# STM32WB55x register map
File version: 1.0
CPU: CM4 r0p1, little endian, 4 interrupt priority bits
Registers are 32-bit, read-write, reset 0x0 unless marked. A register's access mark holds for its fields unless they carry their own. Offsets are from the block's base; [hi:lo] are bit positions; {n}, {i} and the like mark numbered series.

## STK — SysTick timer
Base 0xE000E010
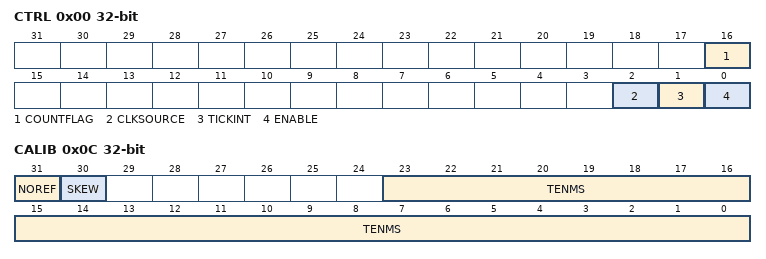
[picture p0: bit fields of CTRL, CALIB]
0x00 CTRL — SysTick control and status register
  [16] COUNTFLAG
  [2] CLKSOURCE — Clock source selection
  [1] TICKINT — SysTick exception request enable
  [0] ENABLE — Counter enable
0x04 LOAD — SysTick reload value register
  [23:0] RELOAD — RELOAD value
0x08 VAL — SysTick current value register
  [23:0] CURRENT — Current counter value
0x0C CALIB — SysTick calibration value register
  [31] NOREF — NOREF flag. Reads as zero
  [30] SKEW — SKEW flag: Indicates whether the TENMS value is exact
  [23:0] TENMS — Calibration value

## FPU — Floting point unit
Base 0xE000EF34
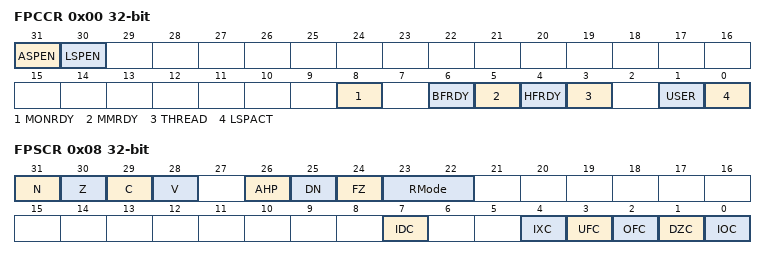
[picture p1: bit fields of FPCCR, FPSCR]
0x00 FPCCR — Floating-point context control register
  [31] ASPEN, [30] LSPEN, [8] MONRDY, [6] BFRDY, [5] MMRDY, [4] HFRDY, [3] THREAD, [1] USER, [0] LSPACT
0x04 FPCAR — Floating-point context address register
  [31:3] ADDRESS — Location of unpopulated floating-point
0x08 FPSCR — Floating-point status control register
  [31] N — Negative condition code flag
  [30] Z — Zero condition code flag
  [29] C — Carry condition code flag
  [28] V — Overflow condition code flag
  [26] AHP — Alternative half-precision control bit
  [25] DN — Default NaN mode control bit
  [24] FZ — Flush-to-zero mode control bit:
  [23:22] RMode — Rounding Mode control field
  [7] IDC — Input denormal cumulative exception bit.
  [4] IXC — Inexact cumulative exception bit
  [3] UFC — Underflow cumulative exception bit
  [2] OFC — Overflow cumulative exception bit
  [1] DZC — Division by zero cumulative exception bit.
  [0] IOC — Invalid operation cumulative exception bit

## NVIC — Nested Vectored Interrupt Controller
Base 0xE000E000
0x04 ICTR ro — Interrupt Controller Type Register
  [3:0] INTLINESNUM — Total number of interrupt lines in groups
{0x100+4i} ISER{i} (i=0..2) — Interrupt Set-Enable Register
  [31:0] SETENA
{0x180+4i} ICER{i} (i=0..2) — Interrupt Clear-Enable Register
  [31:0] CLRENA
{0x200+4i} ISPR{i} (i=0..2) — Interrupt Set-Pending Register
  [31:0] SETPEND
{0x280+4i} ICPR{i} (i=0..2) — Interrupt Clear-Pending Register
  [31:0] CLRPEND
{0x300+4i} IABR{i} ro (i=0..2) — Interrupt Active Bit Register
  [31:0] ACTIVE
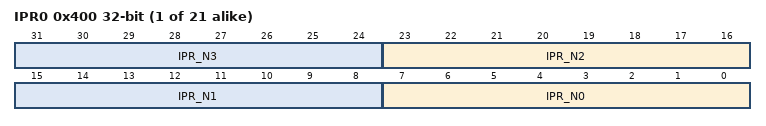
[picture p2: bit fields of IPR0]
{0x400+4i} IPR{i} (i=0..20) — Interrupt Priority Register
  [8n+7:8n] IPR_N{n} (n=0..3)
0xF00 STIR wo — Software Triggered Interrupt Register
  [8:0] INTID — interrupt to be triggered

## DBGMCU — MCU debug component
Base 0xE0042000
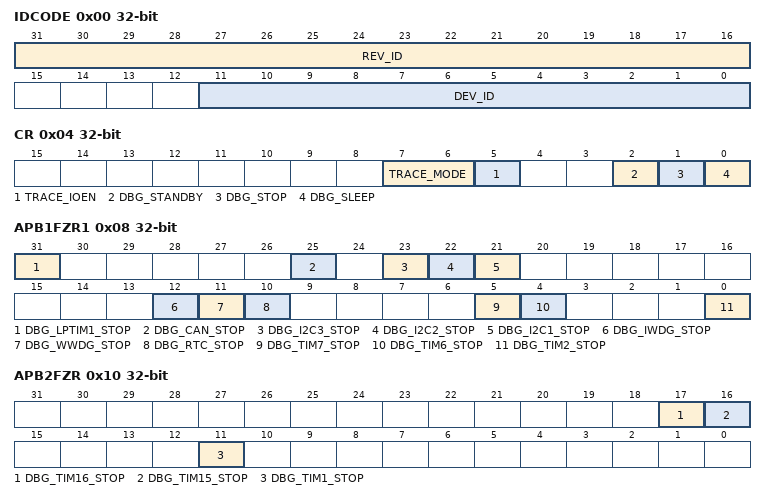
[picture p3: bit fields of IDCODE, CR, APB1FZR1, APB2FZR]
0x00 IDCODE ro — DBGMCU_IDCODE
  [31:16] REV_ID — Revision identifie
  [11:0] DEV_ID — Device identifier
0x04 CR — Debug MCU configuration register
  [7:6] TRACE_MODE — Trace pin assignment control
  [5] TRACE_IOEN — Trace pin assignment control
  [2] DBG_STANDBY — Debug Standby mode
  [1] DBG_STOP — Debug Stop mode
  [0] DBG_SLEEP — Debug Sleep mode
0x08 APB1FZR1 — Debug MCU APB1 freeze register1
  [31] DBG_LPTIM1_STOP — LPTIM1 counter stopped when core is halted
  [25] DBG_CAN_STOP — bxCAN stopped when core is halted
  [23] DBG_I2C3_STOP — I2C3 SMBUS timeout counter stopped when core is halted
  [22] DBG_I2C2_STOP — I2C2 SMBUS timeout counter stopped when core is halted
  [21] DBG_I2C1_STOP — I2C1 SMBUS timeout counter stopped when core is halted
  [12] DBG_IWDG_STOP — Independent watchdog counter stopped when core is halted
  [11] DBG_WWDG_STOP — Window watchdog counter stopped when core is halted
  [10] DBG_RTC_STOP — RTC counter stopped when core is halted
  [5] DBG_TIM7_STOP — TIM7 counter stopped when core is halted
  [4] DBG_TIM6_STOP — TIM6 counter stopped when core is halted
  [0] DBG_TIM2_STOP — TIM2 counter stopped when core is halted
0x0C APB1FZR2 — Debug MCU APB1 freeze register 2
  [5] DBG_LPTIM2_STOP — LPTIM2 counter stopped when core is halted
0x10 APB2FZR — Debug MCU APB2 freeze register
  [17] DBG_TIM16_STOP — TIM16 counter stopped when core is halted
  [16] DBG_TIM15_STOP — TIM15 counter stopped when core is halted
  [11] DBG_TIM1_STOP — TIM1 counter stopped when core is halted
